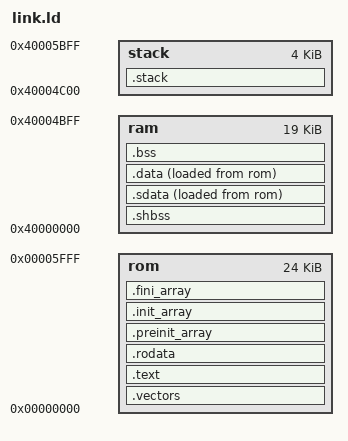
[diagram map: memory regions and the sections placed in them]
OUTPUT_ARCH(riscv)

/* required to correctly link newlib */
GROUP( -lc -lgloss -lgcc -lsupc++ )

SEARCH_DIR(.)
__DYNAMIC  =  0;

MEMORY
{
    rom         : ORIGIN = 0x00000000, LENGTH = 0x6000 /* 24 kB */
    ram       : ORIGIN = 0x40000000, LENGTH = 0x4C00 /* 23 kB */    
    stack       : ORIGIN = 0x40004C00, LENGTH = 0x1000 /* 4 kB */
}

/* Stack information variables */
_min_stack      = 0x1000;   /* 8K - minimum stack space to reserve */
_stack_len     = LENGTH(stack);
_stack_start   = ORIGIN(stack) + LENGTH(stack);

/* We have to align each sector to word boundaries as our current s19->slm
 * conversion scripts are not able to handle non-word aligned sections. */

SECTIONS
{
    .vectors :
    {
        . = ALIGN(4);
        KEEP(*(.vectors))
    } > rom

    .text : {
        . = ALIGN(4);
        _stext = .;
        *(.text)
        *(.text.*)
        _etext  =  .;
        __CTOR_LIST__ = .;
        LONG((__CTOR_END__ - __CTOR_LIST__) / 4 - 2)
        *(.ctors)
        LONG(0)
        __CTOR_END__ = .;
        __DTOR_LIST__ = .;
        LONG((__DTOR_END__ - __DTOR_LIST__) / 4 - 2)
        *(.dtors)
        LONG(0)
        __DTOR_END__ = .;
        *(.lit)
        *(.shdata)
        . = ALIGN(4);
        _endtext = .;
    }  > rom

    .rodata : {
        . = ALIGN(4);
        *(.rodata);
        *(.rodata.*)
    } > rom

    .shbss :
    {
        . = ALIGN(4);
        *(.shbss)
    } > ram

 .preinit_array     :
  {
    PROVIDE_HIDDEN (__preinit_array_start = .);
    KEEP (*(.preinit_array*))
    PROVIDE_HIDDEN (__preinit_array_end = .);
  } >rom
  .init_array :
  {
    PROVIDE_HIDDEN (__init_array_start = .);
    KEEP (*(SORT(.init_array.*)))
    KEEP (*(.init_array*))
    PROVIDE_HIDDEN (__init_array_end = .);
  } >rom
  .fini_array :
  {
    PROVIDE_HIDDEN (__fini_array_start = .);
    KEEP (*(SORT(.fini_array.*)))
    KEEP (*(.fini_array*))
    PROVIDE_HIDDEN (__fini_array_end = .);
  } >rom

  _sidata = LOADADDR(.sdata);

   .sdata : {
        . = ALIGN(4);
         sdata  =  .;
        _sdata  =  .;
       *(.sdata);
        *(.sdata.*)
    } >ram AT> rom

    .data : {
        . = ALIGN(4);

        *(.data);
        *(.data.*)
        edata  =  .;
        _edata  =  .;
    } >ram AT> rom

    .bss :
    {
        . = ALIGN(4);
        _bss_start = .;
        *(.bss)
        *(.bss.*)
        *(.sbss)
        *(.sbss.*)
        *(COMMON)
        _bss_end = .;
    } > ram

    /* ensure there is enough room for stack */
    .stack (NOLOAD): {
        . = ALIGN(4);
        . = . + _min_stack ;
        . = ALIGN(4);
        stack = . ;
        _stack = . ;
    } > stack

    .stab  0 (NOLOAD) :
    {
        [ .stab ]
    }

    .stabstr  0 (NOLOAD) :
    {
        [ .stabstr ]
    }
}
